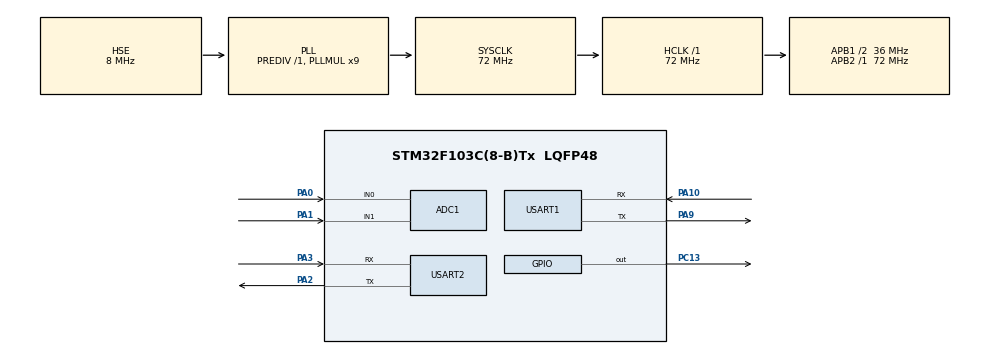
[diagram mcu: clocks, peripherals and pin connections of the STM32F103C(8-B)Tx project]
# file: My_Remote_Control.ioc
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ADC1.Channel-2\#ChannelRegularConversion=ADC_CHANNEL_0
ADC1.Channel-3\#ChannelRegularConversion=ADC_CHANNEL_1
ADC1.ContinuousConvMode=DISABLE
ADC1.ExternalTrigConv=ADC_EXTERNALTRIGCONV_T3_TRGO
ADC1.NbrOfConversion=2
ADC1.NbrOfConversionFlag=1
ADC1.Rank-2\#ChannelRegularConversion=1
ADC1.Rank-3\#ChannelRegularConversion=2
ADC1.SamplingTime-2\#ChannelRegularConversion=ADC_SAMPLETIME_1CYCLE_5
ADC1.SamplingTime-3\#ChannelRegularConversion=ADC_SAMPLETIME_1CYCLE_5
ADC1.master=1
Dma.ADC1.0.Direction=DMA_PERIPH_TO_MEMORY
Dma.ADC1.0.Instance=DMA1_Channel1
Dma.ADC1.0.MemDataAlignment=DMA_MDATAALIGN_HALFWORD
Dma.ADC1.0.MemInc=DMA_MINC_ENABLE
Dma.ADC1.0.Mode=DMA_CIRCULAR
Dma.ADC1.0.PeriphDataAlignment=DMA_PDATAALIGN_HALFWORD
Dma.ADC1.0.PeriphInc=DMA_PINC_DISABLE
Dma.ADC1.0.Priority=DMA_PRIORITY_LOW
Dma.Request0=ADC1
FREERTOS.Tasks01=defaultTask,24,128,StartDefaultTask,Default,NULL,Dynamic,NULL,NULL;display_Task,15,256,display_start_Task,Default,NULL,Dynamic,NULL,NULL;Joystick_Task,8,256,Joystick_start_Task,Default,NULL,Dynamic,NULL,NULL
Mcu.Family=STM32F1
Mcu.Name=STM32F103C(8-B)Tx
Mcu.Package=LQFP48
NVIC.DMA1_Channel1_IRQn=true\:5\:0\:false\:false\:true\:true\:false\:true\:true
NVIC.PriorityGroup=NVIC_PRIORITYGROUP_4
NVIC.TIM1_UP_IRQn=true\:15\:0\:false\:false\:true\:false\:false\:true\:true
NVIC.TimeBase=TIM1_UP_IRQn
NVIC.TimeBaseIP=TIM1
NVIC.USART2_IRQn=true\:5\:0\:false\:false\:true\:true\:true\:true\:true
PA0-WKUP.Signal=ADCx_IN0
PA1.Signal=ADCx_IN1
PA10.Mode=Asynchronous
PA10.Signal=USART1_RX
PA13.Mode=Serial_Wire
PA13.Signal=SYS_JTMS-SWDIO
PA14.Mode=Serial_Wire
PA14.Signal=SYS_JTCK-SWCLK
PA2.Mode=Asynchronous
PA2.Signal=USART2_TX
PA3.Mode=Asynchronous
PA3.Signal=USART2_RX
PA9.Mode=Asynchronous
PA9.Signal=USART1_TX
PC13-TAMPER-RTC.GPIO_ModeDefaultOutputPP=GPIO_MODE_OUTPUT_PP
PC13-TAMPER-RTC.GPIO_PuPd=GPIO_NOPULL
PC13-TAMPER-RTC.PinState=GPIO_PIN_RESET
PC13-TAMPER-RTC.Signal=GPIO_Output
PD0-OSC_IN.Mode=HSE-External-Oscillator
PD0-OSC_IN.Signal=RCC_OSC_IN
PD1-OSC_OUT.Mode=HSE-External-Oscillator
PD1-OSC_OUT.Signal=RCC_OSC_OUT
ProjectManager.HeapSize=0x200
ProjectManager.StackSize=0x400
ProjectManager.TargetToolchain=MDK-ARM V5.32
RCC.ADCPresc=RCC_ADCPCLK2_DIV6
RCC.AHBFreq_Value=72000000
RCC.APB1CLKDivider=RCC_HCLK_DIV2
RCC.APB1Freq_Value=36000000
RCC.APB1TimFreq_Value=72000000
RCC.APB2Freq_Value=72000000
RCC.APB2TimFreq_Value=72000000
RCC.HCLKFreq_Value=72000000
RCC.PLLMUL=RCC_PLL_MUL9
RCC.PLLSourceVirtual=RCC_PLLSOURCE_HSE
RCC.SYSCLKFreq_VALUE=72000000
RCC.SYSCLKSource=RCC_SYSCLKSOURCE_PLLCLK
RCC.USBFreq_Value=72000000
SH.ADCx_IN0.0=ADC1_IN0,IN0
SH.ADCx_IN1.0=ADC1_IN1,IN1
TIM3.Channel-PWM\ Generation4\ No\ Output=TIM_CHANNEL_4
TIM3.Period=100
TIM3.Prescaler=7200-1
TIM3.TIM_MasterOutputTrigger=TIM_TRGO_OC4REF
USART1.VirtualMode=VM_ASYNC
USART2.VirtualMode=VM_ASYNC
VP_FREERTOS_VS_CMSIS_V2.Mode=CMSIS_V2
VP_SYS_VS_tim1.Mode=TIM1
VP_TIM3_VS_no_output4.Mode=PWM Generation4 No Output
board=custom

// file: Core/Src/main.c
/* USER CODE BEGIN Header */
/**
  ******************************************************************************
  * @file           : main.c
  * @brief          : Main program body
  ******************************************************************************
  * @attention
  *
  * Copyright (c) 2024 STMicroelectronics.
  * All rights reserved.
  *
  * This software is licensed under terms that can be found in the LICENSE file
  * in the root directory of this software component.
  * If no LICENSE file comes with this software, it is provided AS-IS.
  *
  ******************************************************************************
  */
/* USER CODE END Header */
#include "main.h"
#include "cmsis_os.h"
#include "adc.h"
#include "dma.h"
#include "tim.h"
#include "usart.h"
#include "gpio.h"

void SystemClock_Config(void);
void MX_FREERTOS_Init(void);

int main(void)
{

  /* MCU Configuration--------------------------------------------------------*/

  /* Reset of all peripherals, Initializes the Flash interface and the Systick. */
  HAL_Init();

  /* Configure the system clock */
  SystemClock_Config();

  /* Initialize all configured peripherals */
  MX_GPIO_Init();
  MX_DMA_Init();
  MX_USART2_UART_Init();
  MX_USART1_UART_Init();
  MX_ADC1_Init();
  MX_TIM3_Init();
  /* USER CODE BEGIN 2 */
//	App_Task_FreeRTOSStart();
  /* USER CODE END 2 */

  /* Init scheduler */
  osKernelInitialize();  /* Call init function for freertos objects (in cmsis_os2.c) */
  MX_FREERTOS_Init();

  /* Start scheduler */
  osKernelStart();

  /* We should never get here as control is now taken by the scheduler */

  /* Infinite loop */
while (1)
	{

    /* USER CODE BEGIN 3 */
	// Debug notes:
	// STM32F103 wiring: GND->GND, TX2(PA2)->screen RX, RX2(PA3)->screen TX, 5V->5V
	// Frame format: 0x55 + command + data + 0xFF 0xFF 0xFF

	}
  /* USER CODE END 3 */
}

void SystemClock_Config(void)
{
  RCC_OscInitTypeDef RCC_OscInitStruct = {0};
  RCC_ClkInitTypeDef RCC_ClkInitStruct = {0};
  RCC_PeriphCLKInitTypeDef PeriphClkInit = {0};

  /** Initializes the RCC Oscillators according to the specified parameters
  * in the RCC_OscInitTypeDef structure.
  */
  RCC_OscInitStruct.OscillatorType = RCC_OSCILLATORTYPE_HSE;
  RCC_OscInitStruct.HSEState = RCC_HSE_ON;
  RCC_OscInitStruct.HSEPredivValue = RCC_HSE_PREDIV_DIV1;
  RCC_OscInitStruct.HSIState = RCC_HSI_ON;
  RCC_OscInitStruct.PLL.PLLState = RCC_PLL_ON;
  RCC_OscInitStruct.PLL.PLLSource = RCC_PLLSOURCE_HSE;
  RCC_OscInitStruct.PLL.PLLMUL = RCC_PLL_MUL9;
  if (HAL_RCC_OscConfig(&RCC_OscInitStruct) != HAL_OK)
  {
    Error_Handler();
  }

  /** Initializes the CPU, AHB and APB buses clocks
  */
  RCC_ClkInitStruct.ClockType = RCC_CLOCKTYPE_HCLK|RCC_CLOCKTYPE_SYSCLK
                              |RCC_CLOCKTYPE_PCLK1|RCC_CLOCKTYPE_PCLK2;
  RCC_ClkInitStruct.SYSCLKSource = RCC_SYSCLKSOURCE_PLLCLK;
  RCC_ClkInitStruct.AHBCLKDivider = RCC_SYSCLK_DIV1;
  RCC_ClkInitStruct.APB1CLKDivider = RCC_HCLK_DIV2;
  RCC_ClkInitStruct.APB2CLKDivider = RCC_HCLK_DIV1;

  if (HAL_RCC_ClockConfig(&RCC_ClkInitStruct, FLASH_LATENCY_2) != HAL_OK)
  {
    Error_Handler();
  }
  PeriphClkInit.PeriphClockSelection = RCC_PERIPHCLK_ADC;
  PeriphClkInit.AdcClockSelection = RCC_ADCPCLK2_DIV6;
  if (HAL_RCCEx_PeriphCLKConfig(&PeriphClkInit) != HAL_OK)
  {
    Error_Handler();
  }
}

void HAL_TIM_PeriodElapsedCallback(TIM_HandleTypeDef *htim)
{
  if (htim->Instance == TIM1)
  {
    HAL_IncTick();
  }
}

void Error_Handler(void)
{
  __disable_irq();
  while (1)
  {
  }
}

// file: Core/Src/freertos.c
/* USER CODE BEGIN Header */
/**
  ******************************************************************************
  * File Name          : freertos.c
  * Description        : Code for freertos applications
  ******************************************************************************
  * @attention
  *
  * Copyright (c) 2026 STMicroelectronics.
  * All rights reserved.
  *
  * This software is licensed under terms that can be found in the LICENSE file
  * in the root directory of this software component.
  * If no LICENSE file comes with this software, it is provided AS-IS.
  *
  ******************************************************************************
  */
/* USER CODE END Header */

#include "FreeRTOS.h"
#include "task.h"
#include "main.h"
#include "cmsis_os.h"

/* USER CODE BEGIN Includes */
#include "App_Display.h"
#include "adc.h"
#include "dma.h"
#include "Com_Datapool.h"
#include "tim.h"
/* USER CODE END Includes */

/* USER CODE BEGIN Variables */

extern uint16_t AdcBuf[2];

/* USER CODE END Variables */
/* Definitions for defaultTask */
osThreadId_t defaultTaskHandle;
const osThreadAttr_t defaultTask_attributes = {
  .name = "defaultTask",
  .stack_size = 128 * 4,
  .priority = (osPriority_t) osPriorityNormal,
};
/* Definitions for display_Task */
osThreadId_t display_TaskHandle;
const osThreadAttr_t display_Task_attributes = {
  .name = "display_Task",
  .stack_size = 256 * 4,
  .priority = (osPriority_t) osPriorityLow7,
};
/* Definitions for Joystick_Task */
osThreadId_t Joystick_TaskHandle;
const osThreadAttr_t Joystick_Task_attributes = {
  .name = "Joystick_Task",
  .stack_size = 256 * 4,
  .priority = (osPriority_t) osPriorityLow,
};

void StartDefaultTask(void *argument);
void display_start_Task(void *argument);
void Joystick_start_Task(void *argument);

void MX_FREERTOS_Init(void); /* (MISRA C 2004 rule 8.1) */

void MX_FREERTOS_Init(void) {

  /* Create the thread(s) */
  /* creation of defaultTask */
  defaultTaskHandle = osThreadNew(StartDefaultTask, NULL, &defaultTask_attributes);

  /* creation of display_Task */
  display_TaskHandle = osThreadNew(display_start_Task, NULL, &display_Task_attributes);

  /* creation of Joystick_Task */
  Joystick_TaskHandle = osThreadNew(Joystick_start_Task, NULL, &Joystick_Task_attributes);

}

void StartDefaultTask(void *argument)
{
  for(;;)
  {
    osDelay(1);
  }
}

void display_start_Task(void *argument)
{
  /* USER CODE BEGIN display_start_Task */
	App_Display_Start();
  /* Infinite loop */
  for(;;)
  {
		App_Display_Show();
    osDelay(1);
  }
  /* USER CODE END display_start_Task */
}

void Joystick_start_Task(void *argument)
{
  /* USER CODE BEGIN Joystick_start_Task */
  /* Infinite loop */
	HAL_ADC_Start_DMA(&hadc1,(uint32_t *)AdcBuf,sizeof(AdcBuf) / sizeof(AdcBuf[0]));
	HAL_TIM_PWM_Start(&htim3, TIM_CHANNEL_4);
__HAL_TIM_SET_COMPARE(&htim3,TIM_CHANNEL_4,90);
  for(;;)
  {
    osDelay(1);
  }
  /* USER CODE END Joystick_start_Task */
}
